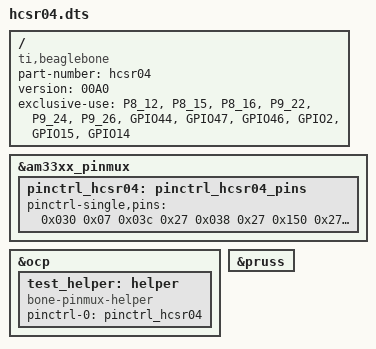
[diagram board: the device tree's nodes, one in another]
/dts-v1/;
/plugin/;

/ {
  compatible = "ti,beaglebone", "ti,beaglebone-black";

  /* identification */
  part-number = "hcsr04";
  version = "00A0";

  exclusive-use =
    "P8_12", "P8_15", "P8_16", "P9_22", "P9_24", "P9_26",
    "GPIO44", "GPIO47", "GPIO46", "GPIO2", "GPIO15", "GPIO14";

  fragment@0 {
    target = <&am33xx_pinmux>;
    __overlay__ {
    pinctrl_hcsr04: pinctrl_hcsr04_pins {
        pinctrl-single,pins = <
					/*
						Table of mux options:
						Bit 0 \
						Bit 1 |- Mode
						Bit 2 /
						Bit 3: 1 - Pull disabled, 0 - Pull enabled
						
						Bit 4: 1 - Pull up, 0 - Pull down
						Bit 5: 1 - Input, 0 – Output

						Format: 0xAddress 0xMuxOptions
					*/
					/* Trigger */
					0x030 0x07 /* P8_12 gpio1[12] GPIO44 out pulldown Mode: 7 */

					/* Echos */
					0x03c 0x27 /* P8_15 gpio1[15] GPIO47 in pulldown Mode: 7 */
					0x038 0x27 /* P8_16 gpio1[14] GPIO46 out pulldown Mode */
					0x150 0x27 /* P9_22 gpio0[2]  GPIO2  in pulldown Mode */
					0x184 0x27 /* P9_24 gpio0[15] GPIO15 out pulldown Mode: 7 */
					0x180 0x27 /* P9_26 gpio0[14] GPIO14 in pulldown Mode: 7 */
          >;
      };
    };
  };

  fragment@1 {
    target = <&ocp>;
    __overlay__ {
      test_helper: helper {
        compatible = "bone-pinmux-helper";
        pinctrl-names = "default";
        pinctrl-0 = <&pinctrl_hcsr04>;
        status = "okay";
      };
    };
  };

  fragment@2{
  target = <&pruss>;
    __overlay__ {
      status = "okay";
    };
  };
};
